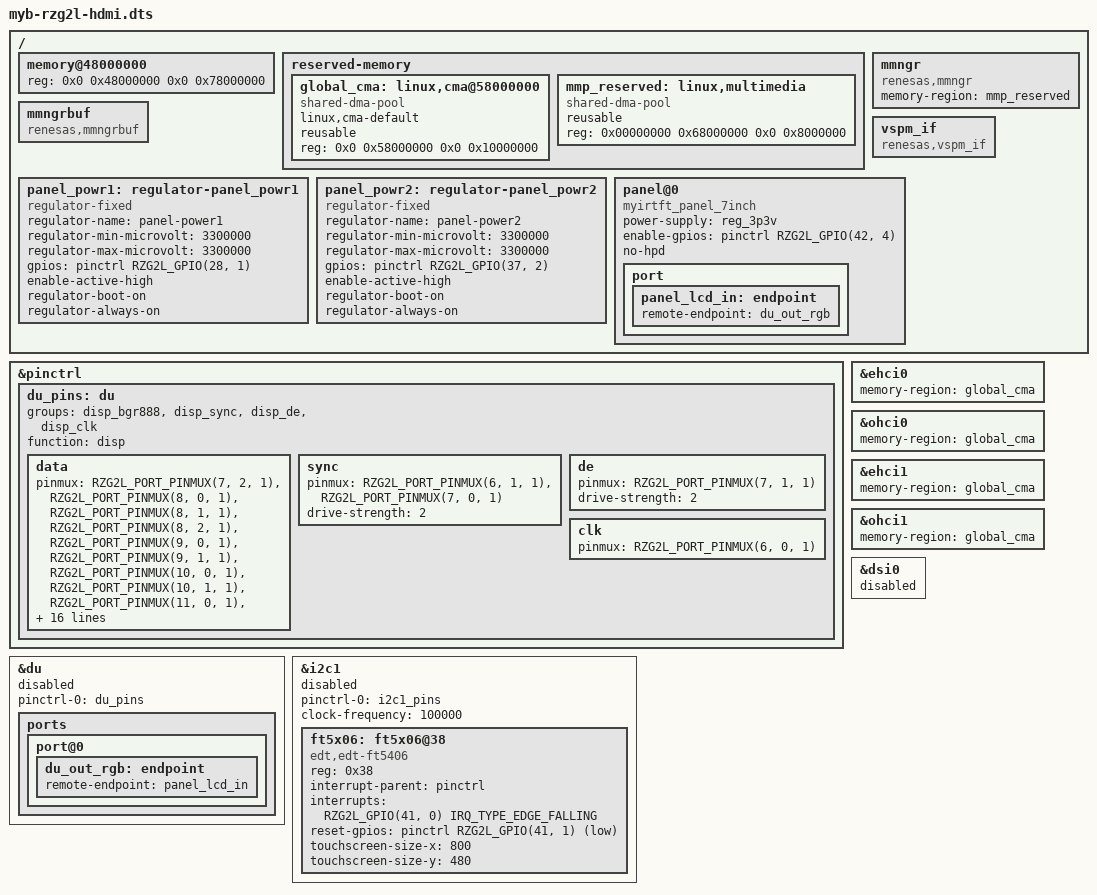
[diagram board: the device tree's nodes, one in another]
// // SPDX-License-Identifier: GPL-2.0
// /*
//  * Device Tree Source for the RZG2L Dual A55 Evaluation board
//  *
//  * Copyright (C) 2022 MYiR Electronics Corp.
//  */

// /dts-v1/;
// #include "noccarc-pm-renesas.dtsi"
// //#include "myb-rzg2l-smarc-base.dtsi"


// / {

// 	memory@48000000 {
// 		device_type = "memory";
// 		/* first 128MB is reserved for secure area. */
// 		reg = <0x0 0x48000000 0x0 0x78000000>;
// 	};

// 	reserved-memory {
// 		#address-cells = <2>;
// 		#size-cells = <2>;
// 		ranges;

// 		global_cma: linux,cma@58000000 {
// 			compatible = "shared-dma-pool";
// 			linux,cma-default;
// 			reusable;
// 			reg = <0x0 0x58000000 0x0 0x10000000>;
// 		};
// 		mmp_reserved: linux,multimedia {
// 			compatible = "shared-dma-pool";
// 			reusable;
// 			reg = <0x00000000 0x68000000 0x0 0x8000000>;
// 		};
// 	};

// 	mmngr {
// 		compatible = "renesas,mmngr";
// 		memory-region = <&mmp_reserved>;
// 	};

// 	mmngrbuf {
// 		compatible = "renesas,mmngrbuf";
// 	};

// 	vspm_if {
// 			compatible = "renesas,vspm_if";
// 	};

// 	sound_card {
// 		//	compatible = "audio-graph-card";
// 			//compatible = "simple-audio-card";
// 		//	dais = <&i2s2_port0>;
// 	};

//     hdmi-out {
//             compatible = "hdmi-connector";
//             type = "d";

//             port {
//                     hdmi_con_out: endpoint {
//                             remote-endpoint = <&lt8912_out>;
//                     };
//             };
//     };
// };

// &pinctrl {

//         ssi1_pins: ssi1 {
//                 pinmux = <RZG2L_PORT_PINMUX(46, 0, 1)>, /* BCK */
//                          <RZG2L_PORT_PINMUX(46, 1, 1)>, /* RCK */
//                          <RZG2L_PORT_PINMUX(46, 2, 1)>, /* TXD */
//                          <RZG2L_PORT_PINMUX(46, 3, 1)>; /* RXD */
//         };

// };

// &ehci0 {
// 	memory-region = <&global_cma>;
// };

// &ohci0 {
// 	memory-region = <&global_cma>;
// };

// &ehci1 {
// 	memory-region = <&global_cma>;
// };

// &ohci1 {
// 	memory-region = <&global_cma>;
// };

// &du {
//     status = "disabled";
// };

// /* MIPI DSI */
// &dsi0 {
// 	status = "disabled";
// 	ports {
// 		port@1 {
// 			dsi0_out: endpoint {
// 				remote-endpoint = <&lt8912_in>;
// 				data-lanes = <1 2 3 4>;
// 			};
// 		};
// 	};
// };


// &ssi1 {
//         pinctrl-0 = <&ssi1_pins>;
//         pinctrl-names = "default";

//         status = "disabled";

//         ports {
//                 i2s2_port0: port@0 {
//                         i2s2_cpu_endpoint: endpoint {
//                                 remote-endpoint = <&codec_endpoint>;
//                                 dai-format = "i2s";
//                         };
//                 };
//         };
// };

// &i2c0 {
//     clock-frequency = <400000>;
//     pinctrl-names = "default";
//     status = "disabled";

// 	/* MIPI-DSI to HDMI and LVDS adapter */
// 	hdmi@48 {
// 		compatible = "lontium,lt8912";
// 		ddc-i2c-bus = <&i2c0>;
// 		dsi-lanes = <4>;
// 		reg = <0x48>;
// 		reset-gpios = <&pinctrl RZG2L_GPIO(42, 2) GPIO_ACTIVE_HIGH>;
// 		hpd-gpios = <&pinctrl RZG2L_GPIO(2, 0) GPIO_ACTIVE_HIGH>;
// 	//	interrupt-parent = <&pinctrl>;
// 	//	interrupts = <RZG2L_GPIO(2, 0) IRQ_TYPE_EDGE_RISING>;

// 	/*  LVDS output or HDMI output
// 		0: lvds
// 		1: hdmi
// 		2: hdmi and lvds
//     */
// 		lvds_mode = <0>;
// 		bit_color = <0> ;    // 0:24bit   1:18bit
// 		hdmi_mode = <1>;     // 0: 1080P  1:720P
// 		audio_mode = <2>;     // 0:NONE   1: SPDIF 2: I2S

// 		display-timings {
// 			native-mode = <&timing0>;
// 			timing0:timing0{
// 					clock-frequency = <72400000>;

// 					hactive = <1280>;
// 					hsync-len = <20>;
// 					hback-porch = <80>;
// 					hfront-porch = <80>;
// 					vactive = <800>;
// 					vsync-len = <15>;
// 					vback-porch = <14>;
// 					vfront-porch = <9>;

// 					vsync-active = <0>;
// 					hsync-active =<0>;
// 					de-active =<0>;
// 					pixelclk-active =<0>;
// 			};

// 		};

// 		ports{
// 			#address-cells = <1>;
// 			#size-cells = <0>;
// 			port@0 {
// 				reg = <0>;
// 				lt8912_in: endpoint@0 {
// 					remote-endpoint = <&dsi0_out>;
// 				};
// 			};

// 			port@1 {
// 				reg = <1>;
// 				lt8912_out: endpoint@1 {
// 					remote-endpoint = <&hdmi_con_out>;
// 				};
// 			};

// 			port@2 {
// 				reg = <2>;
// 				codec_endpoint: endpoint {
// 						remote-endpoint = <&i2s2_cpu_endpoint>;
// 				};
//              };

// 		};

// 	};


//     ft5x06: ft5x06@38 {
//         compatible = "edt,edt-ft5406", "edt,edt-ft5x06";
//             reg = <0x38>;
//             //interrupt-parent = <&pinctrl>;
//             //interrupts = <RZG2L_GPIO(48, 2) IRQ_TYPE_EDGE_FALLING>;
//             reset-gpios = <&pinctrl RZG2L_GPIO(42, 3) GPIO_ACTIVE_LOW>;
//             touchscreen-size-x=<1024>;
//             touchscreen-size-y=<600>;
//     };
// };

// SPDX-License-Identifier: GPL-2.0
/*
 * Device Tree Source for the RZG2L Dual A55 Evaluation board
 *
 * Copyright (C) 2022 MYiR Electronics Corp.
 */

// /dts-v1/;
// #include "noccarc-pm-renesas.dtsi"

// / {

// 	memory@48000000 {
// 		device_type = "memory";
// 		/* first 128MB is reserved for secure area. */
// 		reg = <0x0 0x48000000 0x0 0x78000000>;
// 	};

// 	reserved-memory {
// 		#address-cells = <2>;
// 		#size-cells = <2>;
// 		ranges;

// 		global_cma: linux,cma@58000000 {
// 			compatible = "shared-dma-pool";
// 			linux,cma-default;
// 			reusable;
// 			reg = <0x0 0x58000000 0x0 0x10000000>;
// 		};
// 		mmp_reserved: linux,multimedia {
// 			compatible = "shared-dma-pool";
// 			reusable;
// 			reg = <0x00000000 0x68000000 0x0 0x8000000>;
// 		};
// 	};

// 	mmngr {
// 		compatible = "renesas,mmngr";
// 		memory-region = <&mmp_reserved>;
// 	};

// 	mmngrbuf {
// 		compatible = "renesas,mmngrbuf";
// 	};

// 	vspm_if {
// 			compatible = "renesas,vspm_if";
// 	};

// 	sound_card {
// 		//	compatible = "audio-graph-card";
// 			//compatible = "simple-audio-card";
// 		//	dais = <&i2s2_port0>;
// 	};

//     hdmi-out {
//             compatible = "hdmi-connector";
//             type = "d";

//             port {
//                     hdmi_con_out: endpoint {
//                             remote-endpoint = <&lt8912_out>;
//                     };
//             };
//     };
// };

// &pinctrl {

//         ssi1_pins: ssi1 {
//                 pinmux = <RZG2L_PORT_PINMUX(46, 0, 1)>, /* BCK */
//                          <RZG2L_PORT_PINMUX(46, 1, 1)>, /* RCK */
//                          <RZG2L_PORT_PINMUX(46, 2, 1)>, /* TXD */
//                          <RZG2L_PORT_PINMUX(46, 3, 1)>; /* RXD */
//         };

// };

// &ehci0 {
// 	memory-region = <&global_cma>;
// };

// &ohci0 {
// 	memory-region = <&global_cma>;
// };

// &ehci1 {
// 	memory-region = <&global_cma>;
// };

// &ohci1 {
// 	memory-region = <&global_cma>;
// };

// &du {
//     status = "okay";
// };

/* MIPI DSI */
// &dsi0 {
// 	status = "okay";
// 	ports {
// 		port@1 {
// 			dsi_out: endpoint {
// 				remote-endpoint = <&bridge_in>;
// 				data-lanes = <1 2>;
// 			};
// 		};
// 	};
// };


// &ssi1 {
//         pinctrl-0 = <&ssi1_pins>;
//         pinctrl-names = "default";

//         status = "okay";

//         ports {
//                 i2s2_port0: port@0 {
//                         i2s2_cpu_endpoint: endpoint {
//                                 remote-endpoint = <&codec_endpoint>;
//                                 dai-format = "i2s";
//                         };
//                 };
//         };
// };

// &i2c0 {
//     clock-frequency = <400000>;
//     pinctrl-names = "default";
//     status = "okay";

// 	/* MIPI-DSI to HDMI and LVDS adapter */
// 	hdmi@48 {
// 		compatible = "lontium,lt8912";
// 		ddc-i2c-bus = <&i2c0>;
// 		dsi-lanes = <4>;
// 		reg = <0x48>;
// 		reset-gpios = <&pinctrl RZG2L_GPIO(42, 2) GPIO_ACTIVE_HIGH>;
// 		hpd-gpios = <&pinctrl RZG2L_GPIO(2, 0) GPIO_ACTIVE_HIGH>;
// 	//	interrupt-parent = <&pinctrl>;
// 	//	interrupts = <RZG2L_GPIO(2, 0) IRQ_TYPE_EDGE_RISING>;

// 	/*  LVDS output or HDMI output
// 		0: lvds
// 		1: hdmi
// 		2: hdmi and lvds
//     */
// 		lvds_mode = <0>;
// 		bit_color = <0> ;    // 0:24bit   1:18bit
// 		hdmi_mode = <1>;     // 0: 1080P  1:720P
// 		audio_mode = <2>;     // 0:NONE   1: SPDIF 2: I2S

// 		display-timings {
// 			native-mode = <&timing0>;
// 			timing0:timing0{
// 					clock-frequency = <72400000>;

// 					hactive = <1280>;
// 					hsync-len = <20>;
// 					hback-porch = <80>;
// 					hfront-porch = <80>;
// 					vactive = <800>;
// 					vsync-len = <15>;
// 					vback-porch = <14>;
// 					vfront-porch = <9>;

// 					vsync-active = <0>;
// 					hsync-active =<0>;
// 					de-active =<0>;
// 					pixelclk-active =<0>;
// 			};

// 		};

// 		ports{
// 			#address-cells = <1>;
// 			#size-cells = <0>;
// 			port@0 {
// 				reg = <0>;
// 				lt8912_in: endpoint@0 {
// 					remote-endpoint = <&dsi0_out>;
// 				};
// 			};

// 			port@1 {
// 				reg = <1>;
// 				lt8912_out: endpoint@1 {
// 					remote-endpoint = <&hdmi_con_out>;
// 				};
// 			};

// 			port@2 {
// 				reg = <2>;
// 				codec_endpoint: endpoint {
// 						remote-endpoint = <&i2s2_cpu_endpoint>;
// 				};
//              };

// 		};

// 	};


//     ft5x06: ft5x06@38 {
//         compatible = "edt,edt-ft5406", "edt,edt-ft5x06";
//             reg = <0x38>;
//             interrupt-parent = <&pinctrl>;
//             interrupts = <RZG2L_GPIO(48, 2) IRQ_TYPE_EDGE_FALLING>;
//             reset-gpios = <&pinctrl RZG2L_GPIO(42, 3) GPIO_ACTIVE_LOW>;
//             touchscreen-size-x=<1024>;
//             touchscreen-size-y=<600>;
//     };
// };


/dts-v1/;
#include "noccarc-pm-renesas.dtsi"

/ {

	memory@48000000 {
		device_type = "memory";
		/* first 128MB is reserved for secure area. */
		reg = <0x0 0x48000000 0x0 0x78000000>;
	};

	reserved-memory {
		#address-cells = <2>;
		#size-cells = <2>;
		ranges;

		global_cma: linux,cma@58000000 {
			compatible = "shared-dma-pool";
			linux,cma-default;
			reusable;
			reg = <0x0 0x58000000 0x0 0x10000000>;
		};
		mmp_reserved: linux,multimedia {
			compatible = "shared-dma-pool";
			reusable;
			reg = <0x00000000 0x68000000 0x0 0x8000000>;
		};
	};

	mmngr {
		compatible = "renesas,mmngr";
		memory-region = <&mmp_reserved>;
	};

	mmngrbuf {
		compatible = "renesas,mmngrbuf";
	};

	vspm_if {
			compatible = "renesas,vspm_if";
	};

	panel_powr1: regulator-panel_powr1 {
		compatible = "regulator-fixed";
		regulator-name = "panel-power1";
		regulator-min-microvolt = <3300000>;
		regulator-max-microvolt = <3300000>;
		gpios = <&pinctrl RZG2L_GPIO(28, 1) GPIO_ACTIVE_HIGH>;
		enable-active-high;
		regulator-boot-on;
		regulator-always-on;
	};

	panel_powr2: regulator-panel_powr2 {
		compatible = "regulator-fixed";
		regulator-name = "panel-power2";
		regulator-min-microvolt = <3300000>;
		regulator-max-microvolt = <3300000>;
		gpios = <&pinctrl RZG2L_GPIO(37, 2) GPIO_ACTIVE_HIGH>;
		enable-active-high;
		regulator-boot-on;
		regulator-always-on;
	};
	panel@0 {
		compatible = "myirtft_panel_7inch";
		// backlight = <&lcd_backlight>;
		power-supply = <&reg_3p3v>;
		enable-gpios = <&pinctrl RZG2L_GPIO(42, 4) GPIO_ACTIVE_HIGH>;// backlight
		status = "okay";
		no-hpd;

		port {
			panel_lcd_in: endpoint {
				remote-endpoint = <&du_out_rgb>;
			};
		};
	};
};


&pinctrl {

        du_pins: du {
                groups = "disp_bgr888", "disp_sync", "disp_de", "disp_clk";
                function = "disp";
                data {
                        pinmux = <RZG2L_PORT_PINMUX(7, 2, 1)>,
                                 <RZG2L_PORT_PINMUX(8, 0, 1)>,
                                 <RZG2L_PORT_PINMUX(8, 1, 1)>,
                                 <RZG2L_PORT_PINMUX(8, 2, 1)>,
                                 <RZG2L_PORT_PINMUX(9, 0, 1)>,
                                 <RZG2L_PORT_PINMUX(9, 1, 1)>,
                                 <RZG2L_PORT_PINMUX(10, 0, 1)>,
                                 <RZG2L_PORT_PINMUX(10, 1, 1)>,
                                 <RZG2L_PORT_PINMUX(11, 0, 1)>,
                                 <RZG2L_PORT_PINMUX(11, 1, 1)>,
                                 <RZG2L_PORT_PINMUX(12, 0, 1)>,
                                 <RZG2L_PORT_PINMUX(12, 1, 1)>,
                                 <RZG2L_PORT_PINMUX(13, 0, 1)>,
                                 <RZG2L_PORT_PINMUX(13, 1, 1)>,
                                 <RZG2L_PORT_PINMUX(13, 2, 1)>,
                                 <RZG2L_PORT_PINMUX(14, 0, 1)>,
                                 <RZG2L_PORT_PINMUX(14, 1, 1)>,
                                 <RZG2L_PORT_PINMUX(15, 0, 1)>,
                                 <RZG2L_PORT_PINMUX(15, 1, 1)>,
                                 <RZG2L_PORT_PINMUX(16, 0, 1)>,
                                 <RZG2L_PORT_PINMUX(16, 1, 1)>,
                                 <RZG2L_PORT_PINMUX(17, 0, 1)>,
                                 <RZG2L_PORT_PINMUX(17, 1, 1)>,
                                 <RZG2L_PORT_PINMUX(17, 2, 1)>;
                        drive-strength = <2>;
                };

                sync {
                        pinmux = <RZG2L_PORT_PINMUX(6, 1, 1)>, /* HSYNC */
                                 <RZG2L_PORT_PINMUX(7, 0, 1)>; /* VSYNC */
                        drive-strength = <2>;
                };

                de {
                        pinmux = <RZG2L_PORT_PINMUX(7, 1, 1)>; /* DE */
                        drive-strength = <2>;
                };

                clk {
                        pinmux = <RZG2L_PORT_PINMUX(6, 0, 1)>; /* CLK */
                };
        };
};

&ehci0 {
	memory-region = <&global_cma>;
};

&ohci0 {
	memory-region = <&global_cma>;
};

&ehci1 {
	memory-region = <&global_cma>;
};

&ohci1 {
	memory-region = <&global_cma>;
};

/* MIPI DSI */
&dsi0 {
	status = "disabled";
};


&du {
	pinctrl-0 = <&du_pins>;
	pinctrl-names = "default";
	status = "disabled";

	ports {
		port@0 {
			du_out_rgb: endpoint {
				remote-endpoint = <&panel_lcd_in>;
			};
		};
	};
};

&i2c1 {
	pinctrl-0 = <&i2c1_pins>;
	pinctrl-names = "default";
	clock-frequency = <100000>;
	status = "disabled";

    ft5x06: ft5x06@38 {
        compatible = "edt,edt-ft5406", "edt,edt-ft5x06";
            reg = <0x38>;
            interrupt-parent = <&pinctrl>;
            interrupts = <RZG2L_GPIO(41, 0) IRQ_TYPE_EDGE_FALLING>;
            reset-gpios = <&pinctrl RZG2L_GPIO(41, 1) GPIO_ACTIVE_LOW>;
            touchscreen-size-x=<800>;
            touchscreen-size-y=<480>;
    };


};
